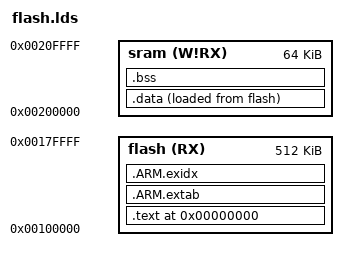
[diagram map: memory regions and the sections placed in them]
/* ----------------------------------------------------------------------------
 *         ATMEL Microcontroller Software Support
 * ----------------------------------------------------------------------------
 * Copyright (c) 2008, Atmel Corporation
 *
 * All rights reserved.
 *
 * Redistribution and use in source and binary forms, with or without
 * modification, are permitted provided that the following conditions are met:
 *
 * - Redistributions of source code must retain the above copyright notice,
 * this list of conditions and the disclaimer below.
 *
 * Atmel's name may not be used to endorse or promote products derived from
 * this software without specific prior written permission.
 *
 * DISCLAIMER: THIS SOFTWARE IS PROVIDED BY ATMEL "AS IS" AND ANY EXPRESS OR
 * IMPLIED WARRANTIES, INCLUDING, BUT NOT LIMITED TO, THE IMPLIED WARRANTIES OF
 * MERCHANTABILITY, FITNESS FOR A PARTICULAR PURPOSE AND NON-INFRINGEMENT ARE
 * DISCLAIMED. IN NO EVENT SHALL ATMEL BE LIABLE FOR ANY DIRECT, INDIRECT,
 * INCIDENTAL, SPECIAL, EXEMPLARY, OR CONSEQUENTIAL DAMAGES (INCLUDING, BUT NOT
 * LIMITED TO, PROCUREMENT OF SUBSTITUTE GOODS OR SERVICES; LOSS OF USE, DATA,
 * OR PROFITS; OR BUSINESS INTERRUPTION) HOWEVER CAUSED AND ON ANY THEORY OF
 * LIABILITY, WHETHER IN CONTRACT, STRICT LIABILITY, OR TORT (INCLUDING
 * NEGLIGENCE OR OTHERWISE) ARISING IN ANY WAY OUT OF THE USE OF THIS SOFTWARE,
 * EVEN IF ADVISED OF THE POSSIBILITY OF SUCH DAMAGE.
 * ----------------------------------------------------------------------------
 */

/*------------------------------------------------------------------------------
 *      Linker script for running in internal Flash on the AT91SAM7S512.
 *----------------------------------------------------------------------------*/

OUTPUT_FORMAT("elf32-littlearm", "elf32-littlearm", "elf32-littlearm")
OUTPUT_ARCH(arm)
ENTRY(entry)

MEMORY
{
    sram (W!RX) : ORIGIN = 0x200000, LENGTH = 0x10000
    flash (RX) : ORIGIN = 0x100000, LENGTH = 0x80000
}

SECTIONS
{
    . = 0;
    _sfixed = .;
    
    .text : {
        *(.text*)
        *(.rodata*)
        . = ALIGN(4);
        PROVIDE(__preinit_array_start = .);
        KEEP(*(.preinit_array))
        PROVIDE(__preinit_array_end = .);
        PROVIDE(__init_array_start = .);
        KEEP(*(SORT(.init_array.*)))
        KEEP(*(.init_array))
        PROVIDE(__init_array_end = .);
    } >flash
    
    .ARM.extab (NOLOAD) : {
        *(.ARM.extab* .gnu.linkonce.armextab.*)
    } >flash
    
    .ARM.exidx (NOLOAD) : {
        __exidx_start = .;
        *(.ARM.exidx* .gnu.linkonce.armexidx.*)
        __exidx_end = .;
    } >flash
    
    _efixed = .;

    .data : {
        _data_lma = LOADADDR(.data);
        _data_start = .;
        KEEP(*(.vectors))
        *(.ramfunc*)
        *(.data*)
        . = ALIGN(4);
        _data_end = .;
    } >sram AT> flash

    .bss (NOLOAD) : {
        _bss_start = .;
        *(.bss*)
        . = ALIGN(4);
        _bss_end = .;
    } >sram
    
    _sstack = 0x210000;
}
end = .;

